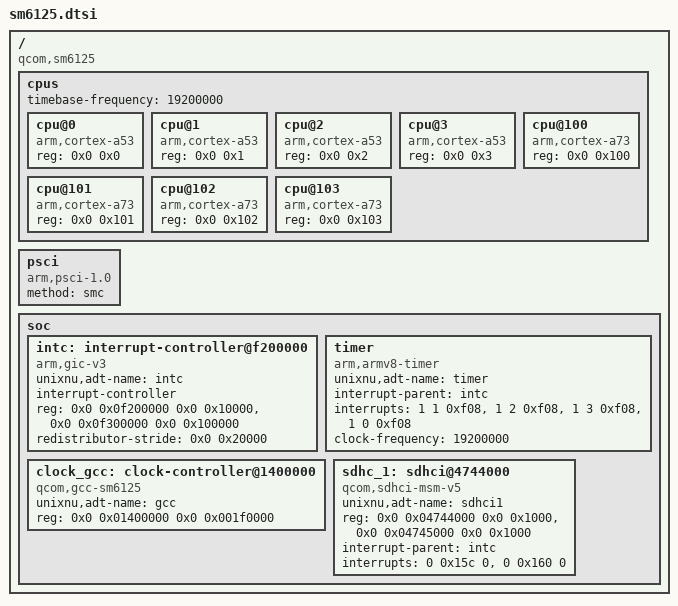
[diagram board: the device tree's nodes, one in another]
/*
 * Base hardware description for Qualcomm SM6125 (Trinket / Nicobar, Snapdragon 665).
 * Kryo 260 (4x Cortex-A53 Silver @ cluster 0 + 4x Cortex-A73 Gold @ cluster 1), ARMv8.0-A.
 * Valores extraidos do stock-fdt.dts e /proc/iomem do aparelho real.
 */

/ {
	#address-cells = <2>;
	#size-cells = <2>;
	compatible = "qcom,sm6125";

	/*
	 * MAX_CPU_CLUSTERS é 1 no build BCM2837 atual (board_config.h), então
	 * unixnu,cluster-type = "P" faz phys_cluster_id = 1 e dispara
	 * assert(phys_cluster_id <= MAX_CPU_CLUSTER_PHY_ID) (ou escrita fora de
	 * bounds na pilha) em ml_parse_cpu_topology() antes da console subir.
	 * Tags E/P só podem voltar junto com patch de MAX_CPU_CLUSTERS >= 2 / AMP.
	 */
	cpus {
		#address-cells = <2>;
		#size-cells = <0>;
		timebase-frequency = <19200000>;

		cpu@0 {
			device_type = "cpu";
			compatible = "arm,cortex-a53";
			reg = <0x0 0x0>;
		};

		cpu@1 {
			device_type = "cpu";
			compatible = "arm,cortex-a53";
			reg = <0x0 0x1>;
		};

		cpu@2 {
			device_type = "cpu";
			compatible = "arm,cortex-a53";
			reg = <0x0 0x2>;
		};

		cpu@3 {
			device_type = "cpu";
			compatible = "arm,cortex-a53";
			reg = <0x0 0x3>;
		};

		cpu@100 {
			device_type = "cpu";
			compatible = "arm,cortex-a73";
			reg = <0x0 0x100>;
		};

		cpu@101 {
			device_type = "cpu";
			compatible = "arm,cortex-a73";
			reg = <0x0 0x101>;
		};

		cpu@102 {
			device_type = "cpu";
			compatible = "arm,cortex-a73";
			reg = <0x0 0x102>;
		};

		cpu@103 {
			device_type = "cpu";
			compatible = "arm,cortex-a73";
			reg = <0x0 0x103>;
		};
	};

	psci {
		compatible = "arm,psci-1.0";
		method = "smc";
	};

	soc {
		#address-cells = <2>;
		#size-cells = <2>;
		ranges;

		/*
		 * SM6125 / stock-fdt.dts: GICv3 e architectural timer com PPIs Qualcomm
		 * (SecPhys = PPI 17, NSPhys = PPI 18, Virt = PPI 19, Hyp = PPI 16).
		 * O override de ArmCpu lê /arm-io/timer para configurar PPI 19 no GICR_ISENABLER0.
		 */
		intc: interrupt-controller@f200000 {
			unixnu,adt-name = "intc";
			compatible = "arm,gic-v3";
			interrupt-controller;
			#interrupt-cells = <3>;
			reg = <0x0 0x0f200000 0x0 0x10000>, <0x0 0x0f300000 0x0 0x100000>;
			redistributor-stride = <0x0 0x20000>;
		};

		timer {
			unixnu,adt-name = "timer";
			compatible = "arm,armv8-timer";
			interrupt-parent = <&intc>;
			interrupts = <1 1 0xf08>, <1 2 0xf08>, <1 3 0xf08>, <1 0 0xf08>;
			clock-frequency = <19200000>;
		};

		/*
		 * SM6125 GCC (0x01400000..0x015f0000) e controlador eMMC SDCC1 (sdhci@4744000).
		 * Mantem /arm-io em base >= 0x01000000 (exigido pelo devicetree.py).
		 */
		clock_gcc: clock-controller@1400000 {
			unixnu,adt-name = "gcc";
			compatible = "qcom,gcc-sm6125", "qcom,gcc-trinket";
			reg = <0x0 0x01400000 0x0 0x001f0000>;
			#clock-cells = <1>;
		};

		sdhc_1: sdhci@4744000 {
			unixnu,adt-name = "sdhci1";
			compatible = "qcom,sdhci-msm-v5";
			reg = <0x0 0x04744000 0x0 0x1000>, <0x0 0x04745000 0x0 0x1000>;
			reg-names = "hc_mem", "cmdq_mem";
			interrupt-parent = <&intc>;
			interrupts = <0 0x15c 0>, <0 0x160 0>;
			interrupt-names = "hc_irq", "pwr_irq";
		};
	};
};
